VERSION ""

NS_ :

BS_:

BU_: K16_BECM K73_TCIC K9_BCM K43_PSCM K17_EBCM K20_ECM K114B_HPCM NEO K124_ASCM EPB XXX Vector__XXX 2

BO_ 189 EBCMRegenPaddle: 7 K17_EBCM
 SG_ RegenPaddle : 7|4@0+ (1,0) [0|0] "" NEO

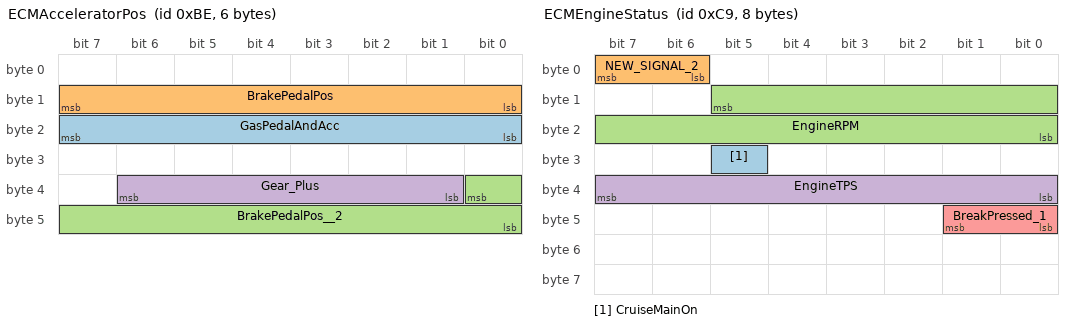
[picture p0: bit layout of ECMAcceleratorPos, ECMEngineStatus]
BO_ 190 ECMAcceleratorPos: 6 K20_ECM
 SG_ GasPedalAndAcc : 23|8@0+ (1,0) [0|0] "" NEO
 SG_ BrakePedalPos : 15|8@0+ (1,0) [0|0] "sticky" NEO
 SG_ BrakePedalPos__2 : 32|9@0- (1,0) [0|1] "" XXX
 SG_ Gear_Plus : 38|6@0+ (1,0) [0|1] "" XXX

BO_ 201 ECMEngineStatus: 8 K20_ECM
 SG_ CruiseMainOn : 29|1@0+ (1,0) [0|1] "" NEO
 SG_ NEW_SIGNAL_2 : 7|2@0+ (1,0) [0|1] "" XXX
 SG_ EngineRPM : 13|14@0+ (0.25,0) [0|0] "RPM" NEO
 SG_ EngineTPS : 39|8@0+ (0.1,0) [0|100.000000065] "%" NEO
 SG_ BreakPressed_1 : 41|2@0+ (1,0) [0|1] "" XXX

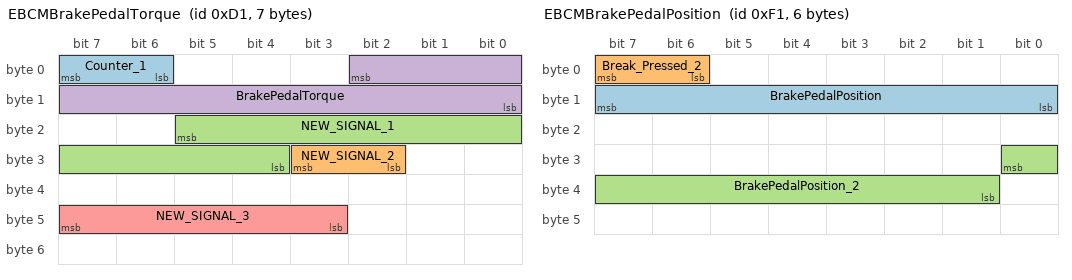
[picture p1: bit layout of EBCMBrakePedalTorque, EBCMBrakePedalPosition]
BO_ 209 EBCMBrakePedalTorque: 7 K17_EBCM
 SG_ Counter_1 : 7|2@0+ (1,0) [0|1] "" XXX
 SG_ NEW_SIGNAL_2 : 27|2@0+ (1,0) [0|1] "" XXX
 SG_ NEW_SIGNAL_1 : 21|10@0- (1,0) [0|1] "" XXX
 SG_ BrakePedalTorque : 2|11@0+ (1,0) [0|0] "" NEO
 SG_ NEW_SIGNAL_3 : 47|5@0+ (1,0) [0|1] "" XXX

BO_ 241 EBCMBrakePedalPosition: 6 K17_EBCM
 SG_ BrakePedalPosition : 15|8@0+ (1,0) [0|255] "" NEO
 SG_ Break_Pressed_2 : 7|2@0+ (1,0) [0|1] "" XXX
 SG_ BrakePedalPosition_2 : 24|8@0+ (1,0) [0|1] "" XXX

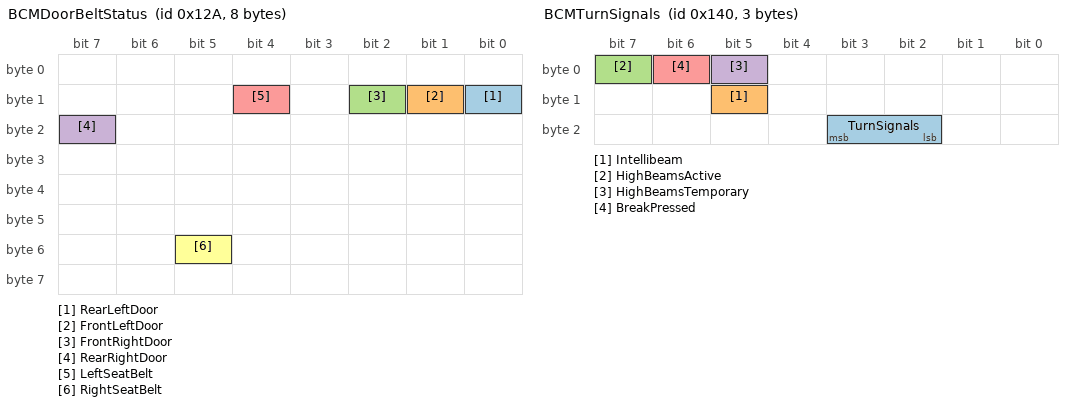
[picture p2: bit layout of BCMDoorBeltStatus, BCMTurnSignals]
BO_ 298 BCMDoorBeltStatus: 8 K9_BCM
 SG_ RearLeftDoor : 8|1@0+ (1,0) [0|0] "" NEO
 SG_ FrontLeftDoor : 9|1@0+ (1,0) [0|0] "" NEO
 SG_ FrontRightDoor : 10|1@0+ (1,0) [0|0] "" NEO
 SG_ RearRightDoor : 23|1@0+ (1,0) [0|0] "" NEO
 SG_ LeftSeatBelt : 12|1@0+ (1,0) [0|0] "" NEO
 SG_ RightSeatBelt : 53|1@0+ (1,0) [0|0] "" NEO

BO_ 309 ECMPRDNL: 8 K20_ECM
 SG_ PRNDL : 2|3@0+ (1,0) [0|0] "" NEO
 SG_ ESPButton : 4|1@0+ (1,0) [0|1] "" XXX

BO_ 320 BCMTurnSignals: 3 K9_BCM
 SG_ TurnSignals : 19|2@0+ (1,0) [0|0] "" NEO
 SG_ Intellibeam : 13|1@0+ (1,0) [0|1] "" XXX
 SG_ HighBeamsActive : 7|1@0+ (1,0) [0|1] "" XXX
 SG_ HighBeamsTemporary : 5|1@0+ (1,0) [0|1] "" XXX
 SG_ BreakPressed : 6|1@0+ (1,0) [0|1] "" XXX

BO_ 328 PSCM_148: 1 K43_PSCM

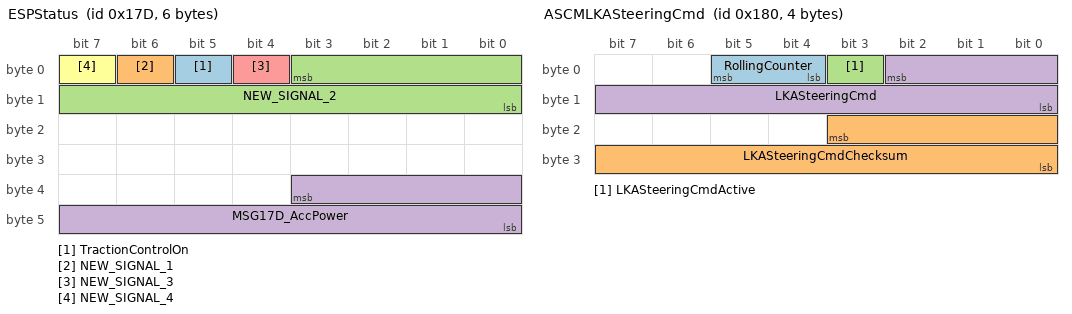
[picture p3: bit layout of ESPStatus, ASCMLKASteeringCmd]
BO_ 381 ESPStatus: 6 K20_ECM
 SG_ TractionControlOn : 5|1@0+ (1,0) [0|0] "" NEO
 SG_ NEW_SIGNAL_1 : 6|1@0+ (1,0) [0|1] "" XXX
 SG_ NEW_SIGNAL_2 : 3|12@0- (1,0) [0|1] "" XXX
 SG_ MSG17D_AccPower : 35|12@0- (1,0) [0|0] "" NEO
 SG_ NEW_SIGNAL_3 : 4|1@0+ (1,0) [0|1] "" XXX
 SG_ NEW_SIGNAL_4 : 7|1@0+ (1,0) [0|1] "" XXX

BO_ 384 ASCMLKASteeringCmd: 4 NEO
 SG_ RollingCounter : 5|2@0+ (1,0) [0|0] "" NEO
 SG_ LKASteeringCmdChecksum : 19|12@0+ (1,0) [0|0] "" NEO
 SG_ LKASteeringCmdActive : 3|1@0+ (1,0) [0|0] "" NEO
 SG_ LKASteeringCmd : 2|11@0- (1,0) [0|0] "" NEO

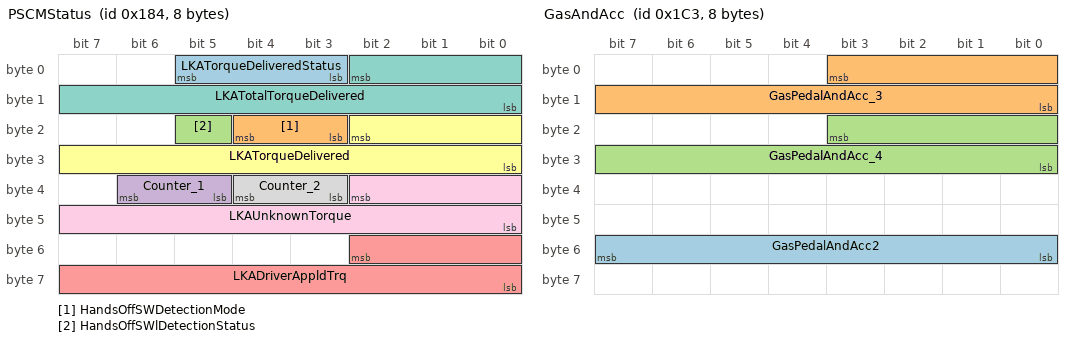
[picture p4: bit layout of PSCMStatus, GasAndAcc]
BO_ 388 PSCMStatus: 8 K43_PSCM
 SG_ LKATorqueDeliveredStatus : 5|3@0+ (1,0) [0|7] "" NEO
 SG_ HandsOffSWDetectionMode : 20|2@0+ (1,0) [0|3] "" NEO
 SG_ HandsOffSWlDetectionStatus : 21|1@0+ (1,0) [0|1] "" NEO
 SG_ Counter_1 : 38|2@0+ (1,0) [0|1] "" XXX
 SG_ LKADriverAppldTrq : 50|11@0- (0.01,0) [-10.24|10.23] "Nm" NEO
 SG_ LKATorqueDelivered : 18|11@0- (0.01,0) [0|0] "" XXX
 SG_ LKATotalTorqueDelivered : 2|11@0- (0.01,0) [-10.24|10.23] "Nm" NEO
 SG_ Counter_2 : 36|2@0+ (1,0) [0|3] "" XXX
 SG_ LKAUnknownTorque : 34|11@0- (0.01,0) [-100|100] "" XXX

BO_ 417 AcceleratorPedal: 8 XXX
 SG_ AcceleratorPedal : 55|8@0+ (1,0) [0|0] "" NEO

BO_ 451 GasAndAcc: 8 XXX
 SG_ GasPedalAndAcc2 : 55|8@0+ (1,0) [0|0] "" NEO
 SG_ GasPedalAndAcc_3 : 3|12@0+ (1,0) [0|1] "" XXX
 SG_ GasPedalAndAcc_4 : 19|12@0+ (1,0) [0|1] "" XXX

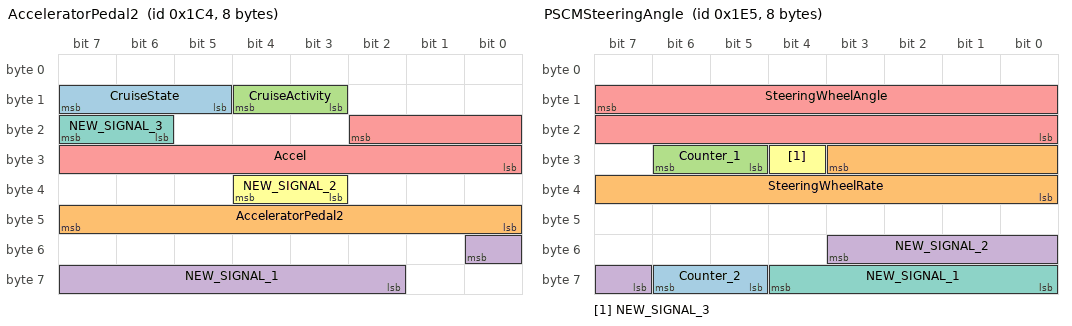
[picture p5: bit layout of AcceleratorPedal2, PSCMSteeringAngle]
BO_ 452 AcceleratorPedal2: 8 XXX
 SG_ CruiseState : 15|3@0+ (1,0) [0|7] "" NEO
 SG_ AcceleratorPedal2 : 47|8@0+ (1,0) [0|0] "" NEO
 SG_ CruiseActivity : 12|2@0+ (1,0) [0|1] "" XXX
 SG_ NEW_SIGNAL_1 : 48|7@0- (1,0) [0|1] "" XXX
 SG_ Accel : 18|11@0+ (1,0) [0|1] "" XXX
 SG_ NEW_SIGNAL_2 : 36|2@0+ (1,0) [0|1] "" XXX
 SG_ NEW_SIGNAL_3 : 23|2@0+ (1,0) [0|1] "" XXX

BO_ 481 ASCMSteeringButton: 7 K124_ASCM
 SG_ DistanceButton : 22|1@0+ (1,0) [0|0] "" NEO
 SG_ LKAButton : 23|1@0+ (1,0) [0|0] "" NEO
 SG_ ACCButtons : 46|3@0+ (1,0) [0|0] "" NEO
 SG_ DriveModeButton : 39|1@0+ (1,0) [0|1] "" XXX
 SG_ Counter_1 : 53|2@0+ (1,0) [0|15] "" XXX
 SG_ Counter_2 : 48|2@1+ (1,0) [0|3] "" XXX
 SG_ Counter_3 : 32|2@1+ (1,0) [0|3] "" XXX
 SG_ Counter_4 : 42|5@1+ (1,0) [0|15] "" XXX
 SG_ Counter_5 : 41|2@0+ (1,0) [0|1] "" XXX

BO_ 485 PSCMSteeringAngle: 8 K43_PSCM
 SG_ Counter_2 : 62|2@0+ (1,0) [0|3] "" XXX
 SG_ SteeringWheelRate : 27|12@0- (0.5,0) [-300|300] "deg/s" NEO
 SG_ Counter_1 : 30|2@0+ (1,0) [0|3] "" XXX
 SG_ NEW_SIGNAL_2 : 51|5@0+ (1,0) [0|1] "" XXX
 SG_ SteeringWheelAngle : 15|16@0- (0.05,0) [-525|525] "deg" NEO
 SG_ NEW_SIGNAL_3 : 28|1@0+ (1,0) [0|1] "" XXX
 SG_ NEW_SIGNAL_1 : 60|5@0+ (1,0) [0|1] "" XXX

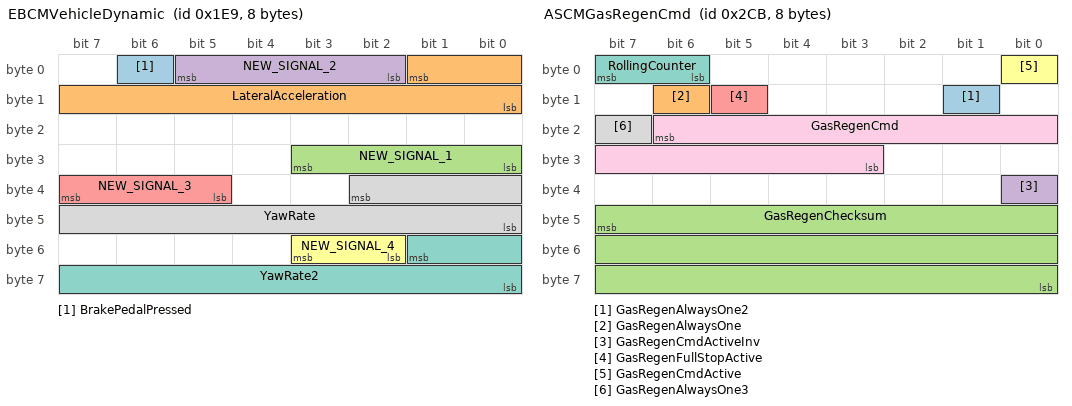
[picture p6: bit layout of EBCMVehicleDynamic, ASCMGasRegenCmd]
BO_ 489 EBCMVehicleDynamic: 8 K17_EBCM
 SG_ BrakePedalPressed : 6|1@0+ (1,0) [0|0] "" NEO
 SG_ LateralAcceleration : 1|10@0- (0.0161,0) [-2047|2047] "m/s2" NEO
 SG_ NEW_SIGNAL_1 : 27|4@0+ (1,0) [0|1] "" XXX
 SG_ NEW_SIGNAL_2 : 5|4@0+ (1,0) [0|1] "" XXX
 SG_ NEW_SIGNAL_3 : 39|3@0+ (1,0) [0|1] "" XXX
 SG_ NEW_SIGNAL_4 : 51|2@0+ (1,0) [0|1] "" XXX
 SG_ YawRate2 : 49|10@0- (0.0625,0) [-2047|2047] "grad/s" NEO
 SG_ YawRate : 34|11@0- (0.1,-5) [-2500|2500] "grad/s" XXX

BO_ 560 EPBStatus: 8 EPB
 SG_ EPBClosed : 12|1@0+ (1,0) [0|1] "" NEO

BO_ 711 BECMBatteryVoltageCurrent: 6 K17_EBCM
 SG_ HVBatteryVoltage : 31|12@0+ (0.125,0) [0|511.875] "V" NEO
 SG_ HVBatteryCurrent : 12|13@0- (0.15,0) [-614.4|614.25] "A" NEO

BO_ 715 ASCMGasRegenCmd: 8 K124_ASCM
 SG_ GasRegenAlwaysOne2 : 9|1@0+ (1,0) [0|1] "" NEO
 SG_ GasRegenAlwaysOne : 14|1@0+ (1,0) [0|1] "" NEO
 SG_ GasRegenChecksum : 47|24@0+ (1,0) [0|0] "" NEO
 SG_ GasRegenCmdActiveInv : 32|1@0+ (1,0) [0|0] "" NEO
 SG_ GasRegenFullStopActive : 13|1@0+ (1,0) [0|0] "" NEO
 SG_ GasRegenCmdActive : 0|1@0+ (1,0) [0|0] "" NEO
 SG_ RollingCounter : 7|2@0+ (1,0) [0|0] "" NEO
 SG_ GasRegenAlwaysOne3 : 23|1@0+ (1,0) [0|1] "" NEO
 SG_ GasRegenCmd : 22|12@0+ (1,0) [0|0] "" NEO

BO_ 717 ASCM_2CD: 5 K124_ASCM

BO_ 810 TCICOnStarGPSPosition: 8 K73_TCIC
 SG_ GPSLongitude : 39|32@0+ (1,0) [0|0] "milliarcsecond" NEO
 SG_ GPSLatitude : 7|32@0+ (1,0) [0|0] "milliarcsecond" NEO

BO_ 840 EBCMWheelSpdFront: 4 K17_EBCM
 SG_ FLWheelSpd : 7|16@0+ (0.0311,0) [0|255] "km/h" NEO
 SG_ FRWheelSpd : 23|16@0+ (0.0311,0) [0|255] "km/h" NEO

BO_ 842 EBCMWheelSpdRear: 4 K17_EBCM
 SG_ RLWheelSpd : 7|16@0+ (0.0311,0) [0|255] "km/h" NEO
 SG_ RRWheelSpd : 23|16@0+ (0.0311,0) [0|255] "km/h" NEO

BO_ 869 ASCM_365: 4 K124_ASCM

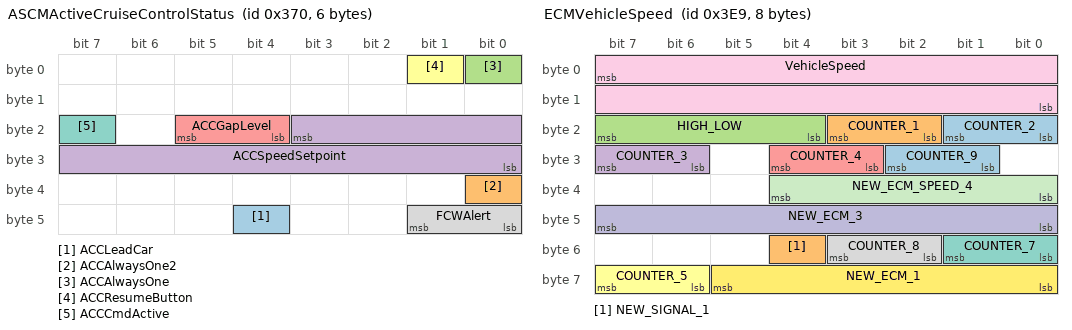
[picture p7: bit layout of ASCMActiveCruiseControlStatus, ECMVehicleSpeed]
BO_ 880 ASCMActiveCruiseControlStatus: 6 K124_ASCM
 SG_ ACCLeadCar : 44|1@0+ (1,0) [0|0] "" Vector__XXX
 SG_ ACCAlwaysOne2 : 32|1@0+ (1,0) [0|0] "" Vector__XXX
 SG_ ACCAlwaysOne : 0|1@0+ (1,0) [0|0] "" Vector__XXX
 SG_ ACCSpeedSetpoint : 19|12@0+ (1,0) [0|0] "km/h" NEO
 SG_ ACCGapLevel : 21|2@0+ (1,0) [0|0] "" NEO
 SG_ ACCResumeButton : 1|1@0+ (1,0) [0|0] "" NEO
 SG_ ACCCmdActive : 23|1@0+ (1,0) [0|0] "" NEO
 SG_ FCWAlert : 41|2@0+ (1,0) [0|3] "" XXX

BO_ 1001 ECMVehicleSpeed: 8 K20_ECM
 SG_ COUNTER_2 : 17|2@0+ (1,0) [0|1] "" XXX
 SG_ COUNTER_1 : 19|2@0+ (1,0) [0|1] "" XXX
 SG_ HIGH_LOW : 23|4@0+ (1,0) [0|1] "" XXX
 SG_ COUNTER_3 : 31|2@0+ (1,0) [0|1] "" XXX
 SG_ COUNTER_4 : 28|2@0+ (1,0) [0|1] "" XXX
 SG_ COUNTER_5 : 63|2@0+ (1,0) [0|1] "" XXX
 SG_ COUNTER_7 : 49|2@0+ (1,0) [0|1] "" XXX
 SG_ COUNTER_8 : 51|2@0+ (1,0) [0|1] "" XXX
 SG_ VehicleSpeed : 7|16@0+ (0.01,0) [0|0] "mph" NEO
 SG_ NEW_ECM_3 : 40|8@1+ (1,0) [-500|500] "" XXX
 SG_ NEW_ECM_SPEED_4 : 36|5@0+ (2.5,0) [0|1] "" XXX
 SG_ NEW_ECM_1 : 61|6@0- (1,0) [-3|3] "" XXX
 SG_ COUNTER_9 : 26|2@0+ (1,0) [0|1] "" XXX
 SG_ NEW_SIGNAL_1 : 52|1@0+ (1,0) [0|1] "" XXX

BO_ 1033 ASCMKeepAlive: 7 NEO
 SG_ ASCMKeepAliveAllZero : 7|56@0+ (1,0) [0|0] "" NEO

BO_ 1034 ASCM_40A: 7 K124_ASCM

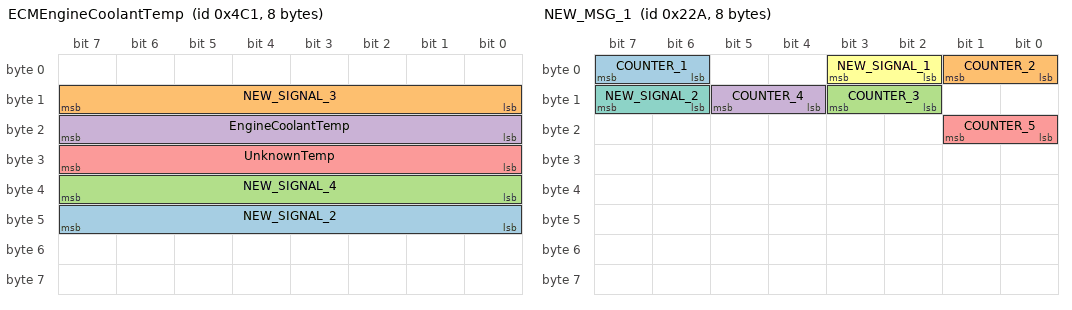
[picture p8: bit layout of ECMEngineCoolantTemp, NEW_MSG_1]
BO_ 1217 ECMEngineCoolantTemp: 8 K20_ECM
 SG_ NEW_SIGNAL_2 : 47|8@0+ (1,0) [0|1] "" XXX
 SG_ NEW_SIGNAL_3 : 15|8@0+ (1,0) [0|1] "" XXX
 SG_ NEW_SIGNAL_4 : 39|8@0+ (1,0) [0|1] "" XXX
 SG_ EngineCoolantTemp : 23|8@0+ (1,-40) [0|0] "°C" NEO
 SG_ UnknownTemp : 31|8@0+ (1,0) [0|1] "" XXX

BO_ 1249 VIN_Part2: 8 K20_ECM
 SG_ VINPart2 : 7|64@0+ (1,0) [0|0] "" NEO

BO_ 1296 ASCM_510: 4 K124_ASCM

BO_ 1300 VIN_Part1: 8 K20_ECM
 SG_ VINPart1 : 7|64@0+ (1,0) [0|0] "" NEO

BO_ 1912 PSCM_778: 8 K43_PSCM
 SG_ NEW_SIGNAL_1 : 13|2@0+ (1,0) [0|1] "" XXX
 SG_ NEW_SIGNAL_2 : 8|1@0+ (1,0) [0|1] "" XXX

BO_ 1930 ASCM_78A: 7 K124_ASCM

BO_ 554 NEW_MSG_1: 8 XXX
 SG_ COUNTER_1 : 7|2@0+ (1,0) [0|1] "" XXX
 SG_ COUNTER_2 : 1|2@0+ (1,0) [0|1] "" XXX
 SG_ COUNTER_3 : 11|2@0+ (1,0) [0|1] "" XXX
 SG_ COUNTER_4 : 13|2@0+ (1,0) [0|1] "" XXX
 SG_ COUNTER_5 : 17|2@0+ (1,0) [0|1] "" XXX
 SG_ NEW_SIGNAL_1 : 3|2@0+ (1,0) [0|1] "" XXX
 SG_ NEW_SIGNAL_2 : 15|2@0+ (1,0) [0|1] "" XXX

BO_ 977 NEW_MSG_2: 8 XXX
 SG_ NEW_SIGNAL_1 : 15|8@0+ (1,0) [0|1] "" XXX
 SG_ NEW_SIGNAL_3 : 34|3@0+ (1,0) [0|1] "" XXX

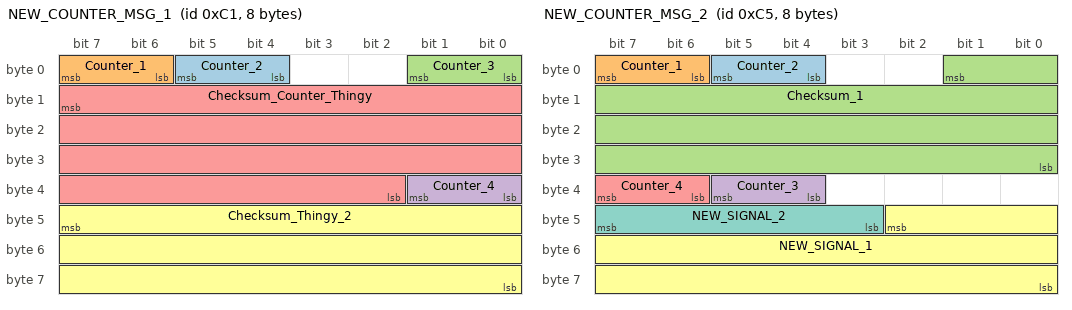
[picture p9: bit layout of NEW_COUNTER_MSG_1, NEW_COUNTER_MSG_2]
BO_ 193 NEW_COUNTER_MSG_1: 8 XXX
 SG_ Counter_2 : 5|2@0+ (1,0) [0|1] "" XXX
 SG_ Counter_1 : 7|2@0+ (1,0) [0|1] "" XXX
 SG_ Counter_3 : 1|2@0+ (1,0) [0|1] "" XXX
 SG_ Counter_4 : 33|2@0+ (1,0) [0|1] "" XXX
 SG_ Checksum_Counter_Thingy : 15|30@0- (1,0) [0|1] "" XXX
 SG_ Checksum_Thingy_2 : 47|24@0- (1,0) [0|1] "" XXX

BO_ 197 NEW_COUNTER_MSG_2: 8 XXX
 SG_ Counter_2 : 5|2@0+ (1,0) [0|1] "" XXX
 SG_ Counter_1 : 7|2@0+ (1,0) [0|1] "" XXX
 SG_ Checksum_1 : 1|26@0+ (1,0) [0|1] "" XXX
 SG_ Counter_3 : 37|2@0+ (1,0) [0|1] "" XXX
 SG_ Counter_4 : 39|2@0+ (1,0) [0|1] "" XXX
 SG_ NEW_SIGNAL_1 : 42|19@0+ (1,0) [0|1] "" XXX
 SG_ NEW_SIGNAL_2 : 47|5@0+ (1,0) [0|1] "" XXX

BO_ 199 NEW_MSG_3: 8 XXX

BO_ 211 NEW_GAS_1: 8 XXX
 SG_ NEW_GAS_MSG_1 : 3|12@0- (1,0) [0|1] "" XXX
 SG_ NEW_SIGNAL_1 : 5|2@0+ (1,0) [0|1] "" XXX

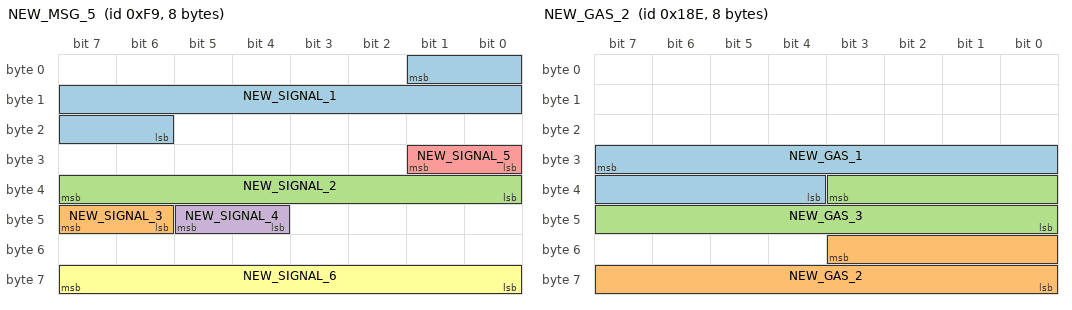
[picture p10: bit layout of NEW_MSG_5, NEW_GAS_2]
BO_ 249 NEW_MSG_5: 8 XXX
 SG_ NEW_SIGNAL_1 : 1|12@0+ (1,0) [0|1] "" XXX
 SG_ NEW_SIGNAL_3 : 47|2@0+ (1,0) [0|1] "" XXX
 SG_ NEW_SIGNAL_2 : 39|8@0+ (1,0) [0|1] "" XXX
 SG_ NEW_SIGNAL_4 : 45|2@0+ (1,0) [0|1] "" XXX
 SG_ NEW_SIGNAL_5 : 25|2@0+ (1,0) [0|1] "" XXX
 SG_ NEW_SIGNAL_6 : 63|8@0- (1,0) [0|1] "" XXX

BO_ 398 NEW_GAS_2: 8 XXX
 SG_ NEW_GAS_1 : 31|12@0+ (1,0) [0|1] "" XXX
 SG_ NEW_GAS_2 : 51|12@0+ (1,0) [0|1] "" XXX
 SG_ NEW_GAS_3 : 35|12@0+ (1,0) [0|1] "" XXX

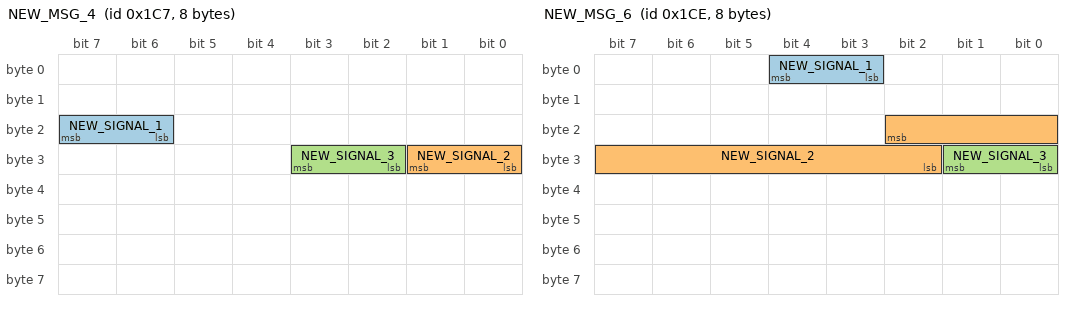
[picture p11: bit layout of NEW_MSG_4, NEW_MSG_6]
BO_ 455 NEW_MSG_4: 8 XXX
 SG_ NEW_SIGNAL_1 : 23|2@0+ (1,0) [0|1] "" XXX
 SG_ NEW_SIGNAL_2 : 25|2@0+ (1,0) [0|1] "" XXX
 SG_ NEW_SIGNAL_3 : 27|2@0+ (1,0) [0|1] "" XXX

BO_ 462 NEW_MSG_6: 8 XXX
 SG_ NEW_SIGNAL_1 : 4|2@0+ (1,0) [0|1] "" XXX
 SG_ NEW_SIGNAL_2 : 18|9@0+ (1,0) [0|1] "" XXX
 SG_ NEW_SIGNAL_3 : 25|2@0+ (1,0) [0|1] "" XXX

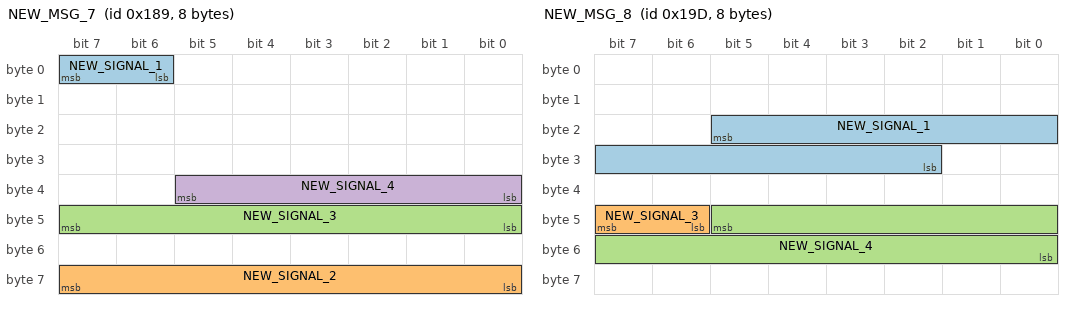
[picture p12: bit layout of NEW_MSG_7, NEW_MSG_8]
BO_ 393 NEW_MSG_7: 8 XXX
 SG_ NEW_SIGNAL_1 : 7|2@0+ (1,0) [0|1] "" XXX
 SG_ NEW_SIGNAL_2 : 63|8@0+ (1,0) [0|1] "" XXX
 SG_ NEW_SIGNAL_3 : 47|8@0+ (1,0) [0|1] "" XXX
 SG_ NEW_SIGNAL_4 : 37|6@0+ (1,0) [0|1] "" XXX

BO_ 413 NEW_MSG_8: 8 XXX
 SG_ NEW_SIGNAL_1 : 21|12@0+ (1,0) [0|1] "" XXX
 SG_ NEW_SIGNAL_3 : 47|2@0+ (1,0) [0|1] "" XXX
 SG_ NEW_SIGNAL_4 : 45|14@0+ (1,0) [0|1] "" XXX

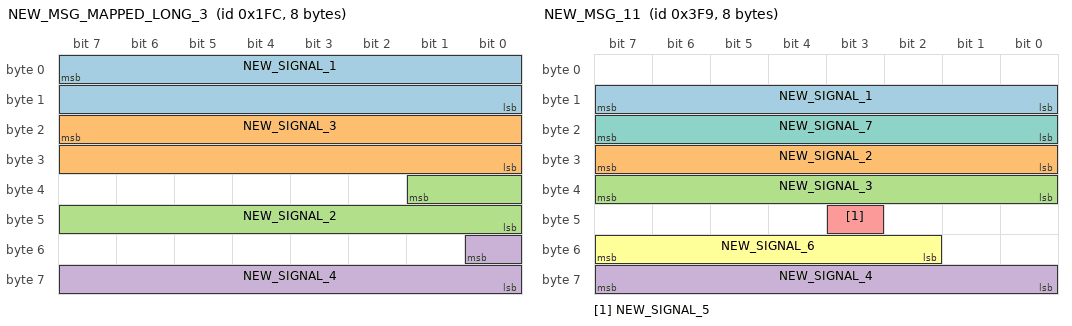
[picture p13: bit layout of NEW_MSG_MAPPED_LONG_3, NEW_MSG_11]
BO_ 508 NEW_MSG_MAPPED_LONG_3: 8 XXX
 SG_ NEW_SIGNAL_1 : 7|16@0- (1,0) [0|1] "" XXX
 SG_ NEW_SIGNAL_3 : 23|16@0- (1,0) [0|1] "" XXX
 SG_ NEW_SIGNAL_2 : 33|10@0+ (1,0) [0|1] "" XXX
 SG_ NEW_SIGNAL_4 : 48|9@0+ (1,0) [0|1] "" XXX

BO_ 1417 NEW_MSG_10: 8 XXX
 SG_ NEW_SIGNAL_3 : 55|16@0+ (1,0) [0|1] "" XXX
 SG_ NEW_SIGNAL_1 : 7|24@0+ (1,0) [0|1] "" XXX

BO_ 1017 NEW_MSG_11: 8 XXX
 SG_ NEW_SIGNAL_1 : 15|8@0+ (1,0) [0|1] "" XXX
 SG_ NEW_SIGNAL_2 : 31|8@0+ (1,0) [0|1] "" XXX
 SG_ NEW_SIGNAL_3 : 39|8@0+ (1,0) [0|1] "" XXX
 SG_ NEW_SIGNAL_4 : 63|8@0+ (1,0) [0|1] "" XXX
 SG_ NEW_SIGNAL_5 : 43|1@0+ (1,0) [0|1] "" XXX
 SG_ NEW_SIGNAL_6 : 55|6@0+ (1,0) [0|1] "" XXX
 SG_ NEW_SIGNAL_7 : 23|8@0+ (1,0) [0|1] "" XXX

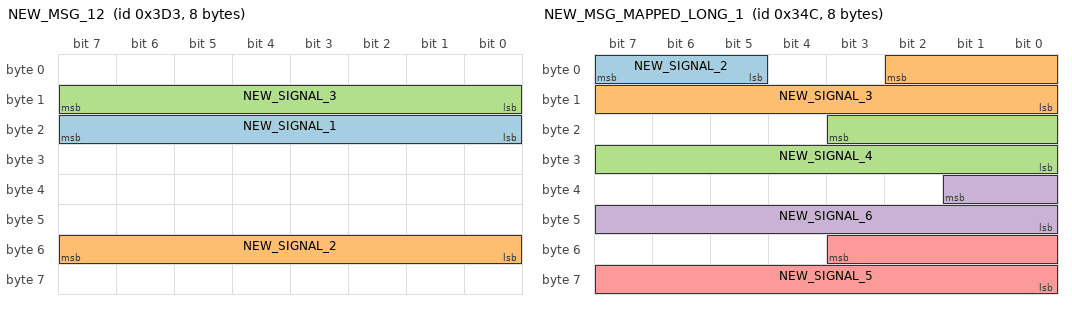
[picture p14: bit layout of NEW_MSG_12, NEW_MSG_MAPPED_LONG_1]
BO_ 979 NEW_MSG_12: 8 XXX
 SG_ NEW_SIGNAL_1 : 23|8@0+ (1,0) [0|1] "" XXX
 SG_ NEW_SIGNAL_2 : 55|8@0+ (1,0) [0|1] "" XXX
 SG_ NEW_SIGNAL_3 : 15|8@0+ (1,0) [0|1] "" XXX

BO_ 844 NEW_MSG_MAPPED_LONG_1: 8 XXX
 SG_ NEW_SIGNAL_2 : 7|3@0+ (1,0) [0|1] "" XXX
 SG_ NEW_SIGNAL_3 : 2|11@0- (1,0) [0|1] "" XXX
 SG_ NEW_SIGNAL_4 : 19|12@0- (1,0) [0|1] "" XXX
 SG_ NEW_SIGNAL_6 : 33|10@0- (1,0) [0|1] "" XXX
 SG_ NEW_SIGNAL_5 : 51|12@0- (1,0) [0|1] "" XXX

BO_ 761 NEW_MSG_13: 8 XXX
 SG_ NEW_SIGNAL_1 : 44|5@0+ (1,0) [0|1] "" XXX

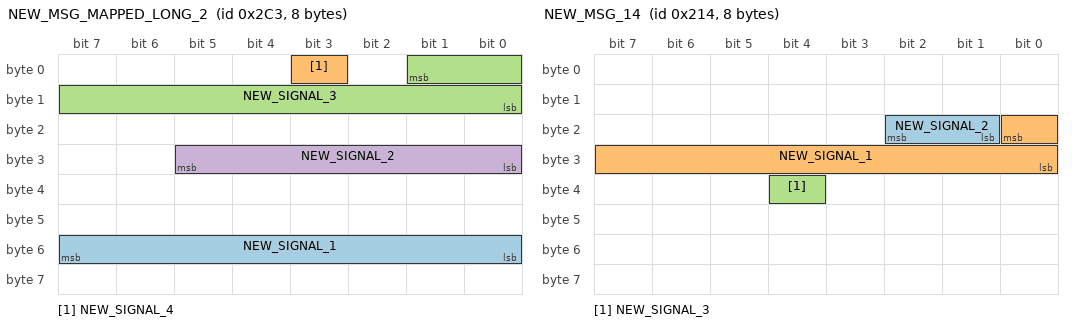
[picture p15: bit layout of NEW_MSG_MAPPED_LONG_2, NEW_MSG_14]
BO_ 707 NEW_MSG_MAPPED_LONG_2: 8 XXX
 SG_ NEW_SIGNAL_1 : 55|8@0+ (1,0) [0|1] "" XXX
 SG_ NEW_SIGNAL_4 : 3|1@0+ (1,0) [0|1] "" XXX
 SG_ NEW_SIGNAL_3 : 1|10@0- (1,0) [0|1] "" XXX
 SG_ NEW_SIGNAL_2 : 29|6@0- (1,0) [0|1] "" XXX

BO_ 532 NEW_MSG_14: 8 XXX
 SG_ NEW_SIGNAL_2 : 18|2@0+ (1,0) [0|1] "" XXX
 SG_ NEW_SIGNAL_1 : 16|9@0- (1,0) [0|1] "" XXX
 SG_ NEW_SIGNAL_3 : 36|1@0+ (1,0) [0|1] "" XXX

BO_ 499 NEW_MSG_9: 8 XXX
 SG_ NEW_SIGNAL_1 : 13|1@0+ (1,0) [0|1] "" XXX

BO_ 647 NEW_MSG_MAPPED_LONG_4: 8 XXX
 SG_ NEW_SIGNAL_1 : 39|8@0- (1,0) [0|1] "" XXX

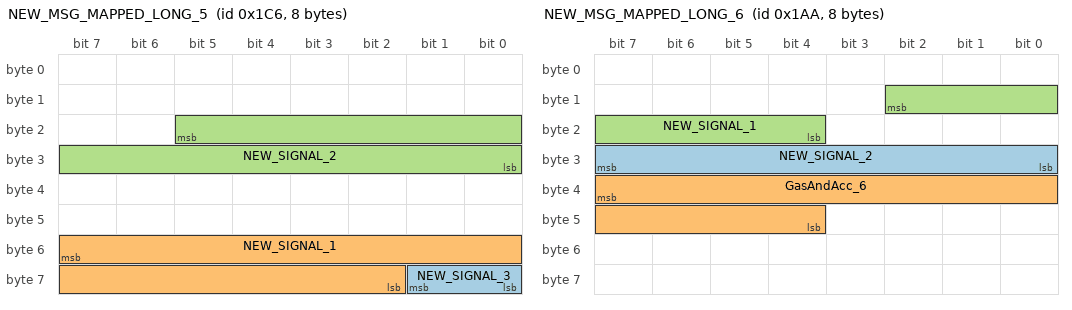
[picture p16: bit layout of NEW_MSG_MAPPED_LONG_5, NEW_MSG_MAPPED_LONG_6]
BO_ 454 NEW_MSG_MAPPED_LONG_5: 8 XXX
 SG_ NEW_SIGNAL_3 : 57|2@0+ (1,0) [0|1] "" XXX
 SG_ NEW_SIGNAL_1 : 55|14@0+ (1,0) [0|1] "" XXX
 SG_ NEW_SIGNAL_2 : 21|14@0- (1,0) [0|1] "" XXX

BO_ 426 NEW_MSG_MAPPED_LONG_6: 8 XXX
 SG_ NEW_SIGNAL_2 : 31|8@0+ (0.01,0) [0|1] "" XXX
 SG_ GasAndAcc_6 : 39|12@0+ (1,0) [0|1] "" XXX
 SG_ NEW_SIGNAL_1 : 10|7@0+ (1,0) [0|1] "" XXX

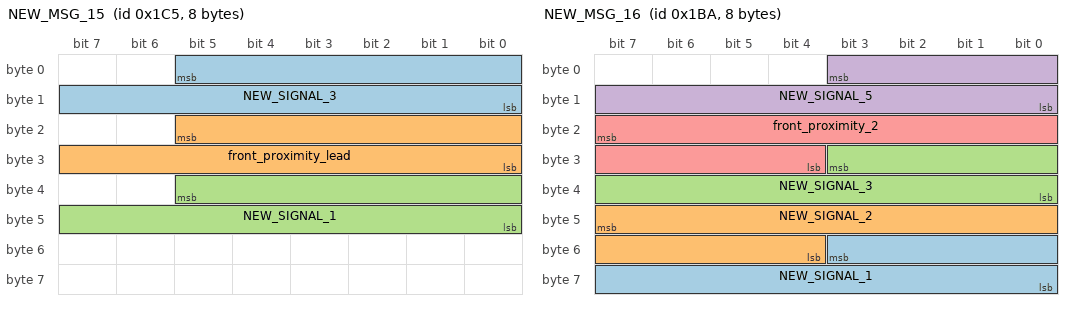
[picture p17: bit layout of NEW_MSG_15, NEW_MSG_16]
BO_ 453 NEW_MSG_15: 8 XXX
 SG_ NEW_SIGNAL_3 : 5|14@0+ (1,0) [0|1] "" XXX
 SG_ front_proximity_lead : 21|14@0+ (1,0) [0|1] "" XXX
 SG_ NEW_SIGNAL_1 : 37|14@0- (1,0) [0|1] "" XXX

BO_ 442 NEW_MSG_16: 8 XXX
 SG_ NEW_SIGNAL_1 : 51|12@0+ (1,0) [0|1] "" XXX
 SG_ NEW_SIGNAL_2 : 47|12@0+ (1,0) [0|1] "" XXX
 SG_ NEW_SIGNAL_3 : 27|12@0+ (1,0) [0|1] "" XXX
 SG_ NEW_SIGNAL_5 : 3|12@0+ (1,0) [0|1] "" XXX
 SG_ front_proximity_2 : 23|12@0+ (0.01,0) [0|1] "" XXX

BO_ 431 NEW_MSG_17: 8 XXX
 SG_ NEW_SIGNAL_1 : 35|12@0- (1,0) [0|1] "" XXX

BO_ 2024 NEW_MSG_18: 8 XXX
 SG_ NEW_SIGNAL_1 : 31|24@0+ (1,0) [0|1] "" XXX
 SG_ NEW_SIGNAL_2 : 2|3@0+ (1,0) [0|1] "" XXX

BO_ 2016 NEW_MSG_19: 8 XXX
 SG_ NEW_SIGNAL_1 : 7|8@0+ (1,0) [0|1] "" XXX

BO_ 1020 NEW_MSG_20: 8 XXX
 SG_ NEW_SIGNAL_1 : 15|8@0+ (1,0) [0|1] "" XXX

BO_ 1003 NEW_MSG_21: 8 XXX
 SG_ NEW_SIGNAL_2 : 39|8@0+ (1,0) [0|1] "" XXX
 SG_ NEW_SIGNAL_1 : 12|5@0- (1,0) [0|1] "" XXX

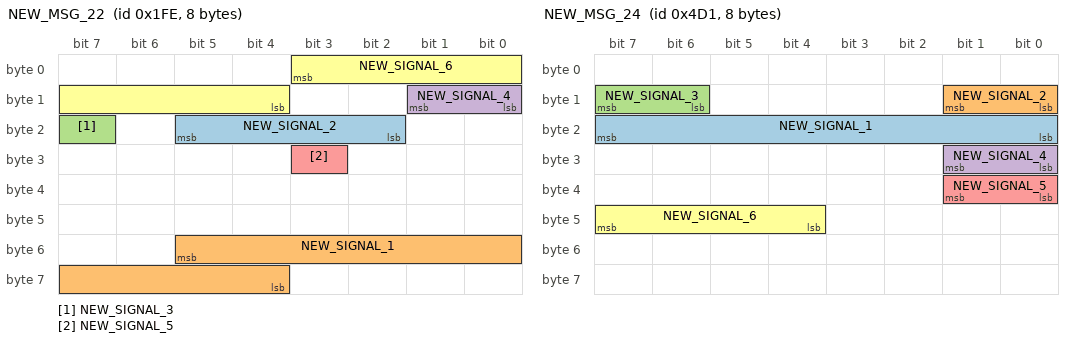
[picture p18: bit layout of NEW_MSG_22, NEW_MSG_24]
BO_ 510 NEW_MSG_22: 8 XXX
 SG_ NEW_SIGNAL_2 : 21|4@0+ (1,0) [0|1] "" XXX
 SG_ NEW_SIGNAL_1 : 53|10@0- (1,0) [0|1] "" XXX
 SG_ NEW_SIGNAL_3 : 23|1@0+ (1,0) [0|1] "" XXX
 SG_ NEW_SIGNAL_4 : 9|2@0+ (1,0) [0|1] "" XXX
 SG_ NEW_SIGNAL_5 : 27|1@0+ (1,0) [0|1] "" XXX
 SG_ NEW_SIGNAL_6 : 3|8@0+ (1,0) [0|1] "" XXX

BO_ 1328 Empty_1: 8 XXX
 SG_ NEW_SIGNAL_1 : 7|32@0+ (1,0) [0|1] "" XXX

BO_ 1322 NEW_MSG_23: 8 XXX

BO_ 1233 NEW_MSG_24: 8 XXX
 SG_ NEW_SIGNAL_1 : 23|8@0+ (1,0) [0|1] "" XXX
 SG_ NEW_SIGNAL_2 : 9|2@0+ (1,0) [0|1] "" XXX
 SG_ NEW_SIGNAL_3 : 15|2@0+ (1,0) [0|1] "" XXX
 SG_ NEW_SIGNAL_4 : 25|2@0+ (1,0) [0|1] "" XXX
 SG_ NEW_SIGNAL_5 : 33|2@0+ (1,0) [0|1] "" XXX
 SG_ NEW_SIGNAL_6 : 47|4@0+ (1,0) [0|1] "" XXX

BO_ 1009 NEW_MSG_25: 8 XXX
 SG_ NEW_SIGNAL_1 : 11|4@0+ (1,0) [0|1] "" XXX

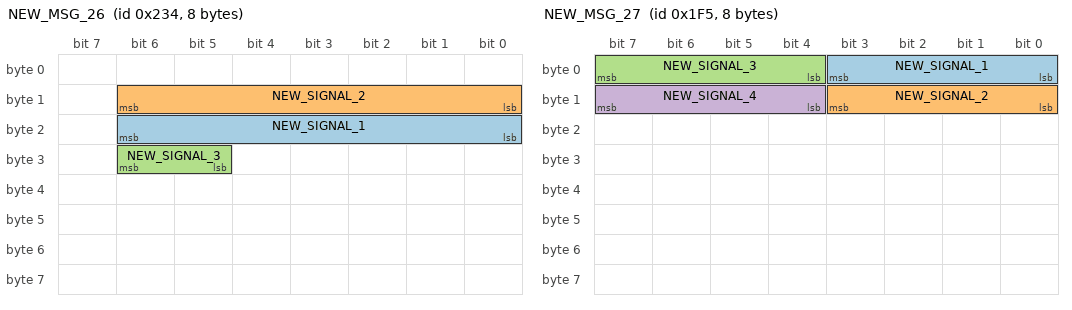
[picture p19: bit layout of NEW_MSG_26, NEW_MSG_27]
BO_ 564 NEW_MSG_26: 8 XXX
 SG_ NEW_SIGNAL_1 : 22|7@0+ (1,0) [0|1] "" XXX
 SG_ NEW_SIGNAL_2 : 14|7@0+ (1,0) [0|1] "" XXX
 SG_ NEW_SIGNAL_3 : 30|2@0+ (1,0) [0|1] "" XXX

BO_ 501 NEW_MSG_27: 8 XXX
 SG_ NEW_SIGNAL_1 : 3|4@0+ (1,0) [0|1] "" XXX
 SG_ NEW_SIGNAL_2 : 11|4@0+ (1,0) [0|1] "" XXX
 SG_ NEW_SIGNAL_3 : 7|4@0+ (1,0) [0|1] "" XXX
 SG_ NEW_SIGNAL_4 : 15|4@0+ (1,0) [0|1] "" XXX

BO_TX_BU_ 384 : K124_ASCM,NEO;
BO_TX_BU_ 715 : NEO,K124_ASCM;
BO_TX_BU_ 880 : NEO,K124_ASCM;
BO_TX_BU_ 1033 : K124_ASCM,NEO;

CM_ BU_ K16_BECM "Battery Energy Control Module";
CM_ BU_ K73_TCIC "Telematics Communication Control Module";
CM_ BU_ K9_BCM "Body Control Module";
CM_ BU_ K43_PSCM "Power Steering Control Module";
CM_ BU_ K17_EBCM "Electronic Brake Control Module";
CM_ BU_ K20_ECM "Engine Control Module";
CM_ BU_ K114B_HPCM "Hybrid Powertrain Control Module";
CM_ BU_ NEO "Comma NEO";
CM_ BU_ K124_ASCM "Active Safety Control Module";CM_ SG_ 190 GasPedalAndAcc "ACC baseline is 62";CM_ SG_ 381 MSG17D_AccPower "Need to investigate";CM_ SG_ 451 GasPedalAndAcc2 "ACC baseline is 62";
VAL_ 309 PRNDL 3 "Reverse" 2 "Drive" 1 "Neutral" 0 "Park" ;
VAL_ 309 ESPButton 1 "Active" 0 "Inactive" ;
VAL_ 320 Intellibeam 1 "Active" 0 "Inactive" ;
VAL_ 320 HighBeamsActive 1 "Active" 0 "Inactive" ;
VAL_ 320 HighBeamsTemporary 1 "Active" 0 "Inactive" ;
VAL_ 384 LKASteeringCmdActive 1 "Active" 0 "Inactive" ;
VAL_ 388 LKATorqueDeliveredStatus 3 "Failed" 2 "Temp. Limited" 1 "Active" 0 "Inactive" ;
VAL_ 388 HandsOffSWDetectionMode 2 "Failed" 1 "Enabled" 0 "Disabled" ;
VAL_ 388 HandsOffSWlDetectionStatus 1 "Hands On" 0 "Hands Off" ;
VAL_ 452 CruiseState 4 "Standstill" 3 "Faulted" 1 "Active" 0 "Off" ;
VAL_ 481 DistanceButton 1 "Active" 0 "Inactive" ;
VAL_ 481 LKAButton 1 "Active" 0 "Inactive" ;
VAL_ 481 ACCButtons 6 "Cancel" 5 "Main" 3 "Set" 2 "Resume" 1 "None" ;
VAL_ 481 DriveModeButton 1 "Active" 0 "Inactive" ;
VAL_ 489 BrakePedalPressed 1 "Pressed" 0 "Depressed" ;
VAL_ 715 GasRegenCmdActiveInv 1 "Inactive" 0 "Active" ;
VAL_ 715 GasRegenCmdActive 1 "Active" 0 "Inactive" ;
VAL_ 880 ACCLeadCar 1 "Present" 0 "Not Present" ;
VAL_ 880 ACCGapLevel 3 "Far" 2 "Med" 1 "Near" 0 "Inactive" ;
VAL_ 880 ACCResumeButton 1 "Pressed" 0 "Depressed" ;
VAL_ 880 ACCCmdActive 1 "Active" 0 "Inactive" ;
